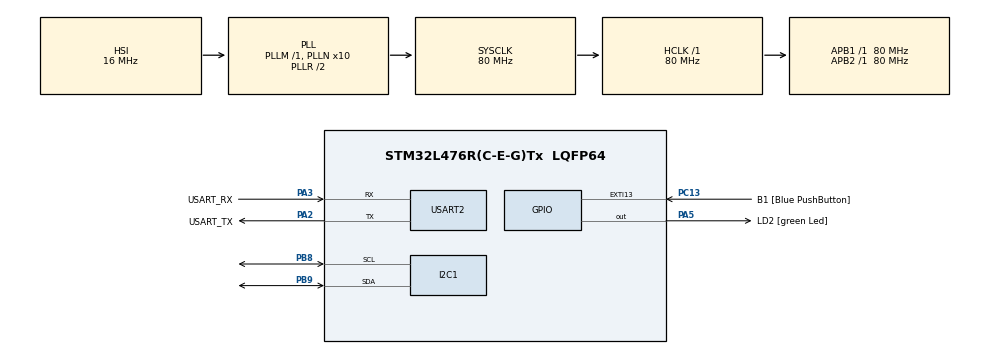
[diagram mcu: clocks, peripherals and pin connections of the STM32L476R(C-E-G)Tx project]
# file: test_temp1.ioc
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I2C1.Timing=0x10909CEC
Mcu.Family=STM32L4
Mcu.Name=STM32L476R(C-E-G)Tx
Mcu.Package=LQFP64
NVIC.PriorityGroup=NVIC_PRIORITYGROUP_4
PA13\ (JTMS-SWDIO).GPIO_Label=TMS
PA13\ (JTMS-SWDIO).Mode=Serial_Wire
PA13\ (JTMS-SWDIO).Signal=SYS_JTMS-SWDIO
PA14\ (JTCK-SWCLK).GPIO_Label=TCK
PA14\ (JTCK-SWCLK).Mode=Serial_Wire
PA14\ (JTCK-SWCLK).Signal=SYS_JTCK-SWCLK
PA2.GPIO_Label=USART_TX
PA2.GPIO_Mode=GPIO_MODE_AF_PP
PA2.GPIO_PuPd=GPIO_NOPULL
PA2.GPIO_Speed=GPIO_SPEED_FREQ_VERY_HIGH
PA2.Mode=Asynchronous
PA2.Signal=USART2_TX
PA3.GPIO_Label=USART_RX
PA3.GPIO_Mode=GPIO_MODE_AF_PP
PA3.GPIO_PuPd=GPIO_NOPULL
PA3.GPIO_Speed=GPIO_SPEED_FREQ_VERY_HIGH
PA3.Mode=Asynchronous
PA3.Signal=USART2_RX
PA5.GPIO_Label=LD2 [green Led]
PA5.GPIO_ModeDefaultOutputPP=GPIO_MODE_OUTPUT_PP
PA5.GPIO_PuPd=GPIO_NOPULL
PA5.GPIO_Speed=GPIO_SPEED_FREQ_LOW
PA5.Signal=GPIO_Output
PB3\ (JTDO-TRACESWO).GPIO_Label=SWO
PB3\ (JTDO-TRACESWO).Signal=SYS_JTDO-SWO
PB8.Mode=I2C
PB8.Signal=I2C1_SCL
PB9.Mode=I2C
PB9.Signal=I2C1_SDA
PC13.GPIO_Label=B1 [Blue PushButton]
PC13.GPIO_ModeDefaultEXTI=GPIO_MODE_IT_FALLING
PC13.GPIO_PuPd=GPIO_NOPULL
PC13.Signal=GPXTI13
PC14-OSC32_IN\ (PC14).Mode=LSE-External-Oscillator
PC14-OSC32_IN\ (PC14).Signal=RCC_OSC32_IN
PC15-OSC32_OUT\ (PC15).Mode=LSE-External-Oscillator
PC15-OSC32_OUT\ (PC15).Signal=RCC_OSC32_OUT
PH0-OSC_IN\ (PH0).Signal=RCC_OSC_IN
PH1-OSC_OUT\ (PH1).Signal=RCC_OSC_OUT
ProjectManager.HeapSize=0x200
ProjectManager.StackSize=0x400
ProjectManager.TargetToolchain=STM32CubeIDE
RCC.ADCFreq_Value=64000000
RCC.AHBFreq_Value=80000000
RCC.APB1Freq_Value=80000000
RCC.APB1TimFreq_Value=80000000
RCC.APB2Freq_Value=80000000
RCC.APB2TimFreq_Value=80000000
RCC.CortexFreq_Value=80000000
RCC.HCLKFreq_Value=80000000
RCC.HSE_VALUE=8000000
RCC.HSI_VALUE=16000000
RCC.MSI_VALUE=4000000
RCC.PLLN=10
RCC.PLLSourceVirtual=RCC_PLLSOURCE_HSI
RCC.PREFETCH_ENABLE=1
RCC.SYSCLKFreq_VALUE=80000000
RCC.SYSCLKSource=RCC_SYSCLKSOURCE_PLLCLK
RCC.USBFreq_Value=64000000
RCC.VCOOutputFreq_Value=160000000
USART2.VirtualMode-Asynchronous=VM_ASYNC
board=NUCLEO-L476RG

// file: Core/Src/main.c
/* USER CODE BEGIN Header */
/**
  ******************************************************************************
  * @file           : main.c
  * @brief          : Main program body
  ******************************************************************************
  * @attention
  *
  * Copyright (c) 2022 STMicroelectronics.
  * All rights reserved.
  *
  * This software is licensed under terms that can be found in the LICENSE file
  * in the root directory of this software component.
  * If no LICENSE file comes with this software, it is provided AS-IS.
  *
  ******************************************************************************
  */
/* USER CODE END Header */
#include "main.h"
#include "i2c.h"
#include "usart.h"
#include "gpio.h"
#include "lib_lcd.h"

UART_HandleTypeDef huart2;

/* USER CODE BEGIN PV */
static const uint8_t TMP102_ADDR = 0x44 << 1; // Use 8-bit address
static const uint8_t REG_TEMP = 0x00;
/* USER CODE END PV */

void SystemClock_Config(void);

int main(void)
{
  /* USER CODE BEGIN 1 */
	  HAL_StatusTypeDef ret;
	  uint8_t buf[12];
	  int16_t val;
	  float temp_c;
	  rgb_lcd* data ;

  /* USER CODE END 1 */

  /* MCU Configuration--------------------------------------------------------*/

  /* Reset of all peripherals, Initializes the Flash interface and the Systick. */
  HAL_Init();

  /* Configure the system clock */
  SystemClock_Config();

  /* Initialize all configured peripherals */
  MX_GPIO_Init();
  MX_USART2_UART_Init();
  MX_I2C1_Init();
  /* USER CODE BEGIN 2 */
  lcd_init(&hi2c1, &data) ;

  /* USER CODE END 2 */

  /* Infinite loop */
  while (1)
  {
/*	HAL_I2C_Master_Transmit(&hi2c1, Add_Sht31, Mes_Demand_Sht31, Size, Timeout);
	HAL_I2C_Master_Receive(&hi2c1, Add_Sht31, Pdata, Size, Timeout);

	lcd_position(&hi2c1,0,0) ;
	lcd_print(&hi2c1, Pdata) ;
	HAL_Delay(1000) ;
*/

	    // Tell TMP102 that we want to read from the temperature register
	    buf[0] = REG_TEMP;
	    ret = HAL_I2C_Master_Transmit(&hi2c1, TMP102_ADDR, buf, 1, HAL_MAX_DELAY);

	    if ( ret != HAL_OK ) { strcpy((char*)buf, "Error Tx\r\n");}
	    else
	    {
	        // Read 2 bytes from the temperature register
	        ret = HAL_I2C_Master_Receive(&hi2c1, TMP102_ADDR, buf, 2, HAL_MAX_DELAY);

	        if ( ret != HAL_OK ) { strcpy((char*)buf, "Error Rx\r\n");}
	        else
	        {
	        //Combine the bytes
	        val = ((int16_t)buf[0] << 4) | (buf[1] >> 4);

	        // Convert to 2's complement, since temperature can be negative
	        if ( val > 0x7FF ) { val |= 0xF000;}

	        // Convert to float temperature value (Celsius)
	        temp_c = val * 0.0625;

	        // Convert temperature to decimal format
	        temp_c *= 100;
	        sprintf((char*)buf, "%u.%u C\r\n", ((unsigned int)temp_c / 100), ((unsigned int)temp_c % 100));
	        }
	    }

	    // Send out buffer (temperature or error message)
	    HAL_UART_Transmit(&huart2, buf, strlen((char*)buf), HAL_MAX_DELAY);

	    // Wait
	    HAL_Delay(500);

		  lcd_position(&hi2c1,0,0) ;
		  lcd_print(&hi2c1, val) ;
		  reglagecouleur(255,0,0) ;
		  HAL_Delay(500) ;

  }
}

void SystemClock_Config(void)
{
  RCC_OscInitTypeDef RCC_OscInitStruct = {0};
  RCC_ClkInitTypeDef RCC_ClkInitStruct = {0};

  /** Configure the main internal regulator output voltage
  */
  if (HAL_PWREx_ControlVoltageScaling(PWR_REGULATOR_VOLTAGE_SCALE1) != HAL_OK)
  {
    Error_Handler();
  }
  /** Initializes the RCC Oscillators according to the specified parameters
  * in the RCC_OscInitTypeDef structure.
  */
  RCC_OscInitStruct.OscillatorType = RCC_OSCILLATORTYPE_HSI;
  RCC_OscInitStruct.HSIState = RCC_HSI_ON;
  RCC_OscInitStruct.HSICalibrationValue = RCC_HSICALIBRATION_DEFAULT;
  RCC_OscInitStruct.PLL.PLLState = RCC_PLL_ON;
  RCC_OscInitStruct.PLL.PLLSource = RCC_PLLSOURCE_HSI;
  RCC_OscInitStruct.PLL.PLLM = 1;
  RCC_OscInitStruct.PLL.PLLN = 10;
  RCC_OscInitStruct.PLL.PLLP = RCC_PLLP_DIV7;
  RCC_OscInitStruct.PLL.PLLQ = RCC_PLLQ_DIV2;
  RCC_OscInitStruct.PLL.PLLR = RCC_PLLR_DIV2;
  if (HAL_RCC_OscConfig(&RCC_OscInitStruct) != HAL_OK)
  {
    Error_Handler();
  }
  /** Initializes the CPU, AHB and APB buses clocks
  */
  RCC_ClkInitStruct.ClockType = RCC_CLOCKTYPE_HCLK|RCC_CLOCKTYPE_SYSCLK
                              |RCC_CLOCKTYPE_PCLK1|RCC_CLOCKTYPE_PCLK2;
  RCC_ClkInitStruct.SYSCLKSource = RCC_SYSCLKSOURCE_PLLCLK;
  RCC_ClkInitStruct.AHBCLKDivider = RCC_SYSCLK_DIV1;
  RCC_ClkInitStruct.APB1CLKDivider = RCC_HCLK_DIV1;
  RCC_ClkInitStruct.APB2CLKDivider = RCC_HCLK_DIV1;

  if (HAL_RCC_ClockConfig(&RCC_ClkInitStruct, FLASH_LATENCY_4) != HAL_OK)
  {
    Error_Handler();
  }
}

void Error_Handler(void)
{
  __disable_irq();
  while (1)
  {
  }
}
